# intmem register map
Vendor: Texas Instruments
Peripheral module from a debugger description file (folder tm4e1111e6pdt).
Registers are 32-bit, read-write, no defined reset value unless marked. A register's access mark holds for its fields unless they carry their own. Offsets are as the file gives them; lines under a group give offsets from that group; [hi:lo] are bit positions; {n}, {i} and the like mark numbered series; 'fields as' and 'values as' point back to an identical list; <NAME> marks a mode.

## INTMEM — Internal Memory register offsets
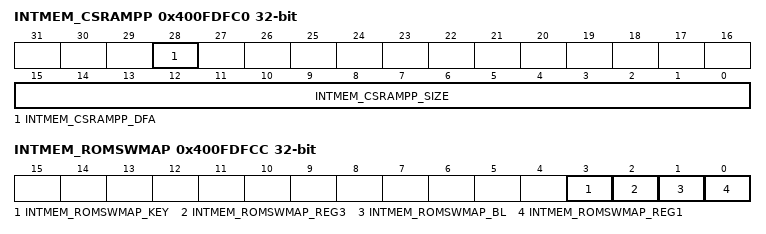
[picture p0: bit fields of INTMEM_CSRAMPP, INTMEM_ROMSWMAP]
0x400FDFC0 INTMEM_CSRAMPP ro — Code SRAM Peripheral Properties
  [28] INTMEM_CSRAMPP_DFA — DMA Code SRAM Access
  [15:0] INTMEM_CSRAMPP_SIZE — Code SRAM Size
    63=INTMEM_CSRAMPP_SIZE_128KB (128 KB of Code SRAM)
0x400FDFC4 INTMEM_SSIZE ro — SRAM Size
  [15:0] INTMEM_SSIZE_SIZE
    127=INTMEM_SSIZE_SIZE_32KB (32 KB of SRAM)
0x400FDFCC INTMEM_ROMSWMAP ro — ROM Third-Party Software
  [3] INTMEM_ROMSWMAP_KEY — Public Key
  [2] INTMEM_ROMSWMAP_REG3 — Region 3 Present
  [1] INTMEM_ROMSWMAP_BL — Boot Loader (Region 2) Present
  [0] INTMEM_ROMSWMAP_REG1 — Region 1 Present
0x400FDFD0 INTMEM_CSRAMDMASZ — Code SRAM DMA Address Size
  [17:0] INTMEM_CSRAMDMASZ_SIZE — uDMA-accessible Memory Size
0x400FDFD4 INTMEM_CSRAMDMAST — Code SRAM DMA Starting Address
  [28:11] INTMEM_CSRAMDMAST_ADDR — Contains the starting address of the Code SRAM region accessible by uDMA if the FLASHPP register DFA bit is set
0x400FE0D4 INTMEM_RVP — Reset Vector Pointer
  [31:0] INTMEM_RVP_RV — Reset Vector Pointer Address
0x400FE0D8 INTMEM_ASR — Application Status
  [0] INTMEM_ASR_EAIM — Execute Application in Memory
0x400FE1D0 INTMEM_BOOTCFG — Boot Configuration
  [1:0] INTMEM_BOOTCFG_DBG — Debug Enable
    0=INTMEM_BOOTCFG_DBG_DISABLED (Debug disabled); 2=INTMEM_BOOTCFG_DBG_ENABLED (Debug enabled)
0x400FE400 INTMEM_CSPPE0 access not given — Code SRAM Protection Program Enable 0
0x400FE404 INTMEM_CSPPE1 access not given — Code SRAM Protection Program Enable 1
